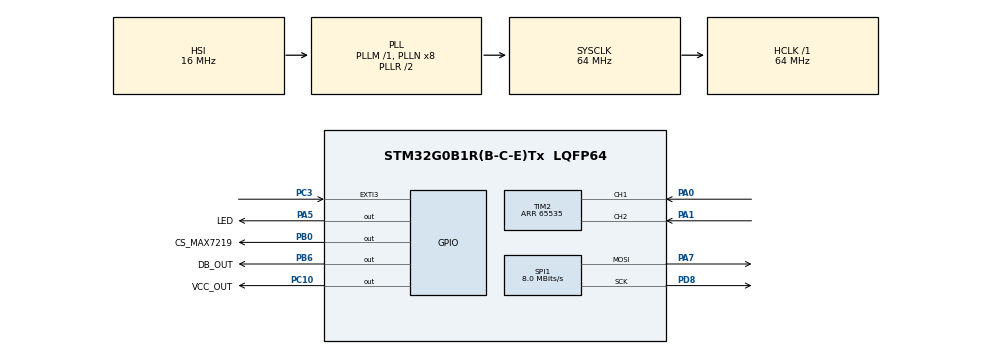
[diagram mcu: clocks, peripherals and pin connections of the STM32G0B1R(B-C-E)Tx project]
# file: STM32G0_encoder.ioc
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Mcu.Family=STM32G0
Mcu.Name=STM32G0B1R(B-C-E)Tx
Mcu.Package=LQFP64
NVIC.EXTI2_3_IRQn=true\:0\:0\:true\:false\:true\:true\:true\:true
NVIC.TIM3_TIM4_IRQn=true\:0\:0\:false\:false\:true\:true\:true\:true
NVIC.TIM6_DAC_LPTIM1_IRQn=true\:3\:0\:false\:false\:true\:false\:true\:true
NVIC.TIM7_LPTIM2_IRQn=true\:0\:0\:false\:false\:true\:true\:true\:true
NVIC.TimeBase=TIM6_DAC_LPTIM1_IRQn
NVIC.TimeBaseIP=TIM6
PA0.GPIO_PuPd=GPIO_NOPULL
PA0.Signal=S_TIM2_CH1_ETR
PA1.GPIO_PuPd=GPIO_NOPULL
PA1.Signal=S_TIM2_CH2
PA5.GPIO_Label=LED
PA5.PinState=GPIO_PIN_SET
PA5.Signal=GPIO_Output
PA7.Mode=TX_Only_Simplex_Unidirect_Master
PA7.Signal=SPI1_MOSI
PB0.GPIO_Label=CS_MAX7219
PB0.Signal=GPIO_Output
PB6.GPIO_Label=DB_OUT
PB6.Signal=GPIO_Output
PC10.GPIO_Label=VCC_OUT
PC10.PinState=GPIO_PIN_SET
PC10.Signal=GPIO_Output
PC3.GPIO_ModeDefaultEXTI=GPIO_MODE_IT_FALLING
PC3.GPIO_PuPd=GPIO_PULLUP
PC3.Signal=GPXTI3
PD8.Mode=TX_Only_Simplex_Unidirect_Master
PD8.Signal=SPI1_SCK
ProjectManager.HeapSize=0x200
ProjectManager.StackSize=0x400
ProjectManager.TargetToolchain=STM32CubeIDE
RCC.ADCFreq_Value=64000000
RCC.AHBFreq_Value=64000000
RCC.CortexFreq_Value=64000000
RCC.EXTERNAL_CLOCK_VALUE=48000
RCC.HCLKFreq_Value=64000000
RCC.HSE_VALUE=8000000
RCC.HSI48_VALUE=48000000
RCC.HSI_VALUE=16000000
RCC.LSE_VALUE=32768
RCC.SYSCLKFreq_VALUE=64000000
RCC.SYSCLKSource=RCC_SYSCLKSOURCE_PLLCLK
RCC.USBFreq_Value=48000000
RCC.VCOOutputFreq_Value=128000000
SH.S_TIM2_CH1_ETR.0=TIM2_CH1,Encoder_Interface
SH.S_TIM2_CH2.0=TIM2_CH2,Encoder_Interface
SPI1.BaudRatePrescaler=SPI_BAUDRATEPRESCALER_8
SPI1.CalculateBaudRate=8.0 MBits/s
SPI1.Direction=SPI_DIRECTION_2LINES
SPI1.Mode=SPI_MODE_MASTER
SPI1.VirtualType=VM_MASTER
TIM2.AutoReloadPreload=TIM_AUTORELOAD_PRELOAD_ENABLE
TIM2.ClockDivision=TIM_CLOCKDIVISION_DIV1
TIM2.EncoderMode=TIM_ENCODERMODE_TI12
TIM2.IC1Filter=10
TIM2.IC1Prescaler=TIM_ICPSC_DIV1
TIM2.IC2Filter=10
TIM2.IC2Prescaler=TIM_ICPSC_DIV1
TIM2.Period=65535
TIM4.AutoReloadPreload=TIM_AUTORELOAD_PRELOAD_ENABLE
TIM4.Period=2000
TIM4.Prescaler=63999
TIM7.AutoReloadPreload=TIM_AUTORELOAD_PRELOAD_ENABLE
TIM7.Period=2000
TIM7.Prescaler=63999
VP_SYS_VS_DBSignals.Mode=DisableDeadBatterySignals
VP_SYS_VS_tim6.Mode=TIM6
VP_TIM4_VS_ClockSourceINT.Mode=Internal
VP_TIM7_VS_ClockSourceINT.Mode=Enable_Timer
board=custom

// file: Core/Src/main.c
/* USER CODE BEGIN Header */
/**
  ******************************************************************************
  * @file           : main.c
  * @brief          : Main program body
  ******************************************************************************
  * @attention
  *
  * Copyright (c) 2024 STMicroelectronics.
  * All rights reserved.
  *
  * This software is licensed under terms that can be found in the LICENSE file
  * in the root directory of this software component.
  * If no LICENSE file comes with this software, it is provided AS-IS.
  *
  ******************************************************************************
  */
/* USER CODE END Header */
#include "main.h"

/* USER CODE BEGIN Includes */
#include <app_encoder.h>
/* USER CODE END Includes */

SPI_HandleTypeDef hspi1;

TIM_HandleTypeDef htim2;
TIM_HandleTypeDef htim4;

void SystemClock_Config(void);
static void MX_GPIO_Init(void);
static void MX_TIM2_Init(void);
static void MX_TIM7_Init(void);
static void MX_SPI1_Init(void);
static void MX_TIM4_Init(void);

int main(void)
{

  /* MCU Configuration--------------------------------------------------------*/

  /* Reset of all peripherals, Initializes the Flash interface and the Systick. */
  HAL_Init();

  /* Configure the system clock */
  SystemClock_Config();

  /* Initialize all configured peripherals */
  MX_GPIO_Init();
  MX_TIM2_Init();
  MX_TIM7_Init();
  MX_SPI1_Init();
  MX_TIM4_Init();
  /* USER CODE BEGIN 2 */
  HAL_TIM_Encoder_Start(&htim2, TIM_CHANNEL_ALL);
  app_encoder_init();
  /* USER CODE END 2 */

  /* Infinite loop */
  /* USER CODE BEGIN WHILE */

  while (1)
  {
	  app_encoder_loop();
    /* USER CODE END WHILE */

  }
}

void SystemClock_Config(void)
{
  RCC_OscInitTypeDef RCC_OscInitStruct = {0};
  RCC_ClkInitTypeDef RCC_ClkInitStruct = {0};

  /** Configure the main internal regulator output voltage
  */
  HAL_PWREx_ControlVoltageScaling(PWR_REGULATOR_VOLTAGE_SCALE1);

  /** Initializes the RCC Oscillators according to the specified parameters
  * in the RCC_OscInitTypeDef structure.
  */
  RCC_OscInitStruct.OscillatorType = RCC_OSCILLATORTYPE_HSI;
  RCC_OscInitStruct.HSIState = RCC_HSI_ON;
  RCC_OscInitStruct.HSIDiv = RCC_HSI_DIV1;
  RCC_OscInitStruct.HSICalibrationValue = RCC_HSICALIBRATION_DEFAULT;
  RCC_OscInitStruct.PLL.PLLState = RCC_PLL_ON;
  RCC_OscInitStruct.PLL.PLLSource = RCC_PLLSOURCE_HSI;
  RCC_OscInitStruct.PLL.PLLM = RCC_PLLM_DIV1;
  RCC_OscInitStruct.PLL.PLLN = 8;
  RCC_OscInitStruct.PLL.PLLP = RCC_PLLP_DIV2;
  RCC_OscInitStruct.PLL.PLLQ = RCC_PLLQ_DIV2;
  RCC_OscInitStruct.PLL.PLLR = RCC_PLLR_DIV2;
  if (HAL_RCC_OscConfig(&RCC_OscInitStruct) != HAL_OK)
  {
    Error_Handler();
  }

  /** Initializes the CPU, AHB and APB buses clocks
  */
  RCC_ClkInitStruct.ClockType = RCC_CLOCKTYPE_HCLK|RCC_CLOCKTYPE_SYSCLK
                              |RCC_CLOCKTYPE_PCLK1;
  RCC_ClkInitStruct.SYSCLKSource = RCC_SYSCLKSOURCE_PLLCLK;
  RCC_ClkInitStruct.AHBCLKDivider = RCC_SYSCLK_DIV1;
  RCC_ClkInitStruct.APB1CLKDivider = RCC_HCLK_DIV1;

  if (HAL_RCC_ClockConfig(&RCC_ClkInitStruct, FLASH_LATENCY_2) != HAL_OK)
  {
    Error_Handler();
  }
}

static void MX_SPI1_Init(void)
{

  /* SPI1 parameter configuration*/
  hspi1.Instance = SPI1;
  hspi1.Init.Mode = SPI_MODE_MASTER;
  hspi1.Init.Direction = SPI_DIRECTION_2LINES;
  hspi1.Init.DataSize = SPI_DATASIZE_8BIT;
  hspi1.Init.CLKPolarity = SPI_POLARITY_LOW;
  hspi1.Init.CLKPhase = SPI_PHASE_1EDGE;
  hspi1.Init.NSS = SPI_NSS_SOFT;
  hspi1.Init.BaudRatePrescaler = SPI_BAUDRATEPRESCALER_8;
  hspi1.Init.FirstBit = SPI_FIRSTBIT_MSB;
  hspi1.Init.TIMode = SPI_TIMODE_DISABLE;
  hspi1.Init.CRCCalculation = SPI_CRCCALCULATION_DISABLE;
  hspi1.Init.CRCPolynomial = 7;
  hspi1.Init.CRCLength = SPI_CRC_LENGTH_DATASIZE;
  hspi1.Init.NSSPMode = SPI_NSS_PULSE_ENABLE;
  if (HAL_SPI_Init(&hspi1) != HAL_OK)
  {
    Error_Handler();
  }

}

static void MX_TIM2_Init(void)
{

  TIM_Encoder_InitTypeDef sConfig = {0};
  TIM_MasterConfigTypeDef sMasterConfig = {0};

  htim2.Instance = TIM2;
  htim2.Init.Prescaler = 0;
  htim2.Init.CounterMode = TIM_COUNTERMODE_UP;
  htim2.Init.Period = 65535;
  htim2.Init.ClockDivision = TIM_CLOCKDIVISION_DIV1;
  htim2.Init.AutoReloadPreload = TIM_AUTORELOAD_PRELOAD_ENABLE;
  sConfig.EncoderMode = TIM_ENCODERMODE_TI12;
  sConfig.IC1Polarity = TIM_ICPOLARITY_RISING;
  sConfig.IC1Selection = TIM_ICSELECTION_DIRECTTI;
  sConfig.IC1Prescaler = TIM_ICPSC_DIV1;
  sConfig.IC1Filter = 10;
  sConfig.IC2Polarity = TIM_ICPOLARITY_RISING;
  sConfig.IC2Selection = TIM_ICSELECTION_DIRECTTI;
  sConfig.IC2Prescaler = TIM_ICPSC_DIV1;
  sConfig.IC2Filter = 10;
  if (HAL_TIM_Encoder_Init(&htim2, &sConfig) != HAL_OK)
  {
    Error_Handler();
  }
  sMasterConfig.MasterOutputTrigger = TIM_TRGO_RESET;
  sMasterConfig.MasterSlaveMode = TIM_MASTERSLAVEMODE_DISABLE;
  if (HAL_TIMEx_MasterConfigSynchronization(&htim2, &sMasterConfig) != HAL_OK)
  {
    Error_Handler();
  }

}

static void MX_TIM4_Init(void)
{

  TIM_ClockConfigTypeDef sClockSourceConfig = {0};
  TIM_MasterConfigTypeDef sMasterConfig = {0};

  htim4.Instance = TIM4;
  htim4.Init.Prescaler = 63999;
  htim4.Init.CounterMode = TIM_COUNTERMODE_UP;
  htim4.Init.Period = 2000;
  htim4.Init.ClockDivision = TIM_CLOCKDIVISION_DIV1;
  htim4.Init.AutoReloadPreload = TIM_AUTORELOAD_PRELOAD_ENABLE;
  if (HAL_TIM_Base_Init(&htim4) != HAL_OK)
  {
    Error_Handler();
  }
  sClockSourceConfig.ClockSource = TIM_CLOCKSOURCE_INTERNAL;
  if (HAL_TIM_ConfigClockSource(&htim4, &sClockSourceConfig) != HAL_OK)
  {
    Error_Handler();
  }
  sMasterConfig.MasterOutputTrigger = TIM_TRGO_RESET;
  sMasterConfig.MasterSlaveMode = TIM_MASTERSLAVEMODE_DISABLE;
  if (HAL_TIMEx_MasterConfigSynchronization(&htim4, &sMasterConfig) != HAL_OK)
  {
    Error_Handler();
  }

}

static void MX_TIM7_Init(void)
{

  LL_TIM_InitTypeDef TIM_InitStruct = {0};

  /* Peripheral clock enable */
  LL_APB1_GRP1_EnableClock(LL_APB1_GRP1_PERIPH_TIM7);

  /* TIM7 interrupt Init */
  NVIC_SetPriority(TIM7_LPTIM2_IRQn, 0);
  NVIC_EnableIRQ(TIM7_LPTIM2_IRQn);

  TIM_InitStruct.Prescaler = 63999;
  TIM_InitStruct.CounterMode = LL_TIM_COUNTERMODE_UP;
  TIM_InitStruct.Autoreload = 2000;
  LL_TIM_Init(TIM7, &TIM_InitStruct);
  LL_TIM_EnableARRPreload(TIM7);
  LL_TIM_SetTriggerOutput(TIM7, LL_TIM_TRGO_RESET);
  LL_TIM_DisableMasterSlaveMode(TIM7);

}

static void MX_GPIO_Init(void)
{
  GPIO_InitTypeDef GPIO_InitStruct = {0};

  /* GPIO Ports Clock Enable */
  __HAL_RCC_GPIOC_CLK_ENABLE();
  __HAL_RCC_GPIOA_CLK_ENABLE();
  __HAL_RCC_GPIOB_CLK_ENABLE();
  __HAL_RCC_GPIOD_CLK_ENABLE();

  /*Configure GPIO pin Output Level */
  HAL_GPIO_WritePin(LED_GPIO_Port, LED_Pin, GPIO_PIN_SET);

  /*Configure GPIO pin Output Level */
  HAL_GPIO_WritePin(GPIOB, CS_MAX7219_Pin|DB_OUT_Pin, GPIO_PIN_RESET);

  /*Configure GPIO pin Output Level */
  HAL_GPIO_WritePin(VCC_OUT_GPIO_Port, VCC_OUT_Pin, GPIO_PIN_SET);

  /*Configure GPIO pin : PC3 */
  GPIO_InitStruct.Pin = GPIO_PIN_3;
  GPIO_InitStruct.Mode = GPIO_MODE_IT_FALLING;
  GPIO_InitStruct.Pull = GPIO_PULLUP;
  HAL_GPIO_Init(GPIOC, &GPIO_InitStruct);

  /*Configure GPIO pin : LED_Pin */
  GPIO_InitStruct.Pin = LED_Pin;
  GPIO_InitStruct.Mode = GPIO_MODE_OUTPUT_PP;
  GPIO_InitStruct.Pull = GPIO_NOPULL;
  GPIO_InitStruct.Speed = GPIO_SPEED_FREQ_LOW;
  HAL_GPIO_Init(LED_GPIO_Port, &GPIO_InitStruct);

  /*Configure GPIO pins : CS_MAX7219_Pin DB_OUT_Pin */
  GPIO_InitStruct.Pin = CS_MAX7219_Pin|DB_OUT_Pin;
  GPIO_InitStruct.Mode = GPIO_MODE_OUTPUT_PP;
  GPIO_InitStruct.Pull = GPIO_NOPULL;
  GPIO_InitStruct.Speed = GPIO_SPEED_FREQ_LOW;
  HAL_GPIO_Init(GPIOB, &GPIO_InitStruct);

  /*Configure GPIO pin : VCC_OUT_Pin */
  GPIO_InitStruct.Pin = VCC_OUT_Pin;
  GPIO_InitStruct.Mode = GPIO_MODE_OUTPUT_PP;
  GPIO_InitStruct.Pull = GPIO_NOPULL;
  GPIO_InitStruct.Speed = GPIO_SPEED_FREQ_LOW;
  HAL_GPIO_Init(VCC_OUT_GPIO_Port, &GPIO_InitStruct);

  /* EXTI interrupt init*/
  HAL_NVIC_SetPriority(EXTI2_3_IRQn, 0, 0);
  HAL_NVIC_EnableIRQ(EXTI2_3_IRQn);

}

void HAL_TIM_PeriodElapsedCallback(TIM_HandleTypeDef *htim)
{
  if (htim->Instance == TIM6) {
    HAL_IncTick();
  }
}

void Error_Handler(void)
{
  __disable_irq();
  while (1)
  {
  }
}
